# STM32WL54xx register map
File version: 1.0
Registers are 32-bit, read-write, reset 0x0 unless marked. A register's access mark holds for its fields unless they carry their own. Offsets are from the block's base; [hi:lo] are bit positions; {n}, {i} and the like mark numbered series.

## AES — AES hardware accelerator
Base 0x58001800
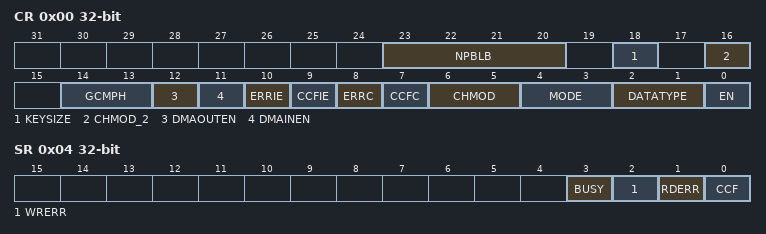
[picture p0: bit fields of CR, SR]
0x00 CR — AES control register
  [23:20] NPBLB — Number of padding bytes in last payload block
  [18] KEYSIZE — Key size selection
  [16] CHMOD_2 — AES Chaining Mode
  [14:13] GCMPH — GCM Phase
  [12] DMAOUTEN — Enable data output phase DMA management
  [11] DMAINEN — Enable data input phase DMA management
  [10] ERRIE — Error Interrupt Enable
  [9] CCFIE — Computation Complete Flag Interrupt Enable
  [8] ERRC — Error Clear
  [7] CCFC — Computation Complete Flag Clear
  [6:5] CHMOD — AES Chaining Mode
  [4:3] MODE — AES Mode Of Operation
  [2:1] DATATYPE — Data type selection
  [0] EN — AES Enable
0x04 SR — AES status register
  [3] BUSY — Busy Flag
  [2] WRERR — Write Error Flag
  [1] RDERR — Read Error Flag
  [0] CCF — Computation Complete Flag
0x08 DINR — AES data input register
  [31:0] DINR — AES Data Input Register
0x0C DOUTR — AES data output register
  [31:0] DOUTR — AES Data Output Register
{0x10+4i} KEYR{i} (i=0..3) — AES key register {i}
  [31:0] KEYR{i} — AES Key Register {i}
{0x20+4i} IVR{i} (i=0..3) — AES initialization vector register {i}
  [31:0] IVR{i} — AES Initialization Vector Register {i}
{0x20+4i} KEYR{i} (i=4..7) — AES key register {i}
  [31:0] KEYR{i} — AES Key Register {i}
{0x40+4i} SUSP{i}R (i=0..7) — AES Suspend register {i}
  [31:0] SUSP{i}R — AES Suspend registers {i}

## PKA — Public Key Accelerator (PKA)
Base 0x58002000
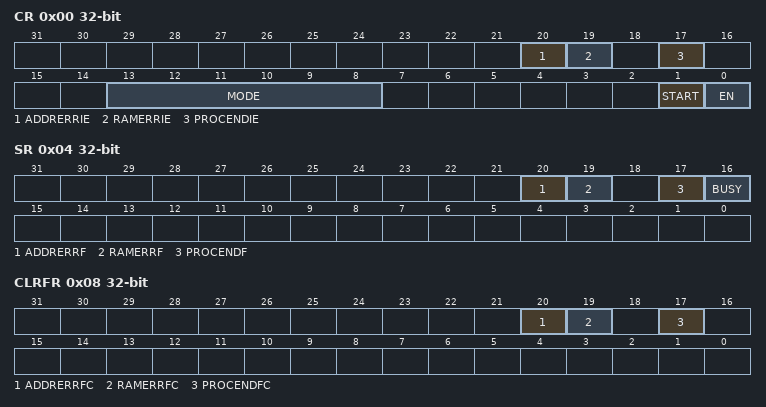
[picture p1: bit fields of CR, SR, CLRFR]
0x00 CR — PKA control register
  [20] ADDRERRIE — RAM error interrupt enable
  [19] RAMERRIE — RAM error interrupt enable
  [17] PROCENDIE — End of operation interrupt enable
  [13:8] MODE — MODE[5:0] PKA operation code
  [1] START — Start operation
  [0] EN — PKA enable
0x04 SR — PKA status register
  [20] ADDRERRF — Address error flag
  [19] RAMERRF — PKA RAM error flag
  [17] PROCENDF — PKA end of operation flag
  [16] BUSY — PKA operation is in progress
0x08 CLRFR — PKA clear flag register
  [20] ADDRERRFC — Clear address error flag
  [19] RAMERRFC — Clear PKA RAM error flag
  [17] PROCENDFC — Clear PKA end of operation flag
{0x400+4i} RAM[{i}] (i=0..893)

## GTZC_TZSC — Global Security Controller
Base 0x58004400
0x00 CR — TZSC control register
  [0] LCK
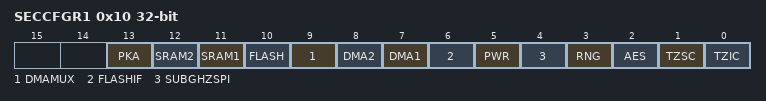
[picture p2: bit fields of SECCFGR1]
0x10 SECCFGR1 — TZSC secure configuration register 1
  [13] PKA, [12] SRAM2, [11] SRAM1, [10] FLASH, [9] DMAMUX, [8] DMA2, [7] DMA1, [6] FLASHIF, [5] PWR, [4] SUBGHZSPI, [3] RNG, [2] AES, [1] TZSC, [0] TZIC
0x20 PRIVCFGR1 — TZSC privilege configuration register 1
0x130 MPCWM1_UPWMR — TZSC Unprivileged Water Mark 1 register
0x134 MPCWM1_UPWWMR — TZSC Unprivileged Writable Water Mark 1 register
0x138 MPCWM2_UPWMR — TZSC Unprivileged Water Mark 2 register
0x140 MPCWM3_UPWMR — TZSC Unprivileged Water Mark 2 register

## GTZC_TZIC
Base 0x58004800
0x00 IER1 — TZIC interrupt enable register 1
0x10 MISR1 — TZIC interrupt status register 1
0x20 ICR1 — TZIC interrupt clear register 1

## DBGMCU — Debug MCU
Base 0xE0042000
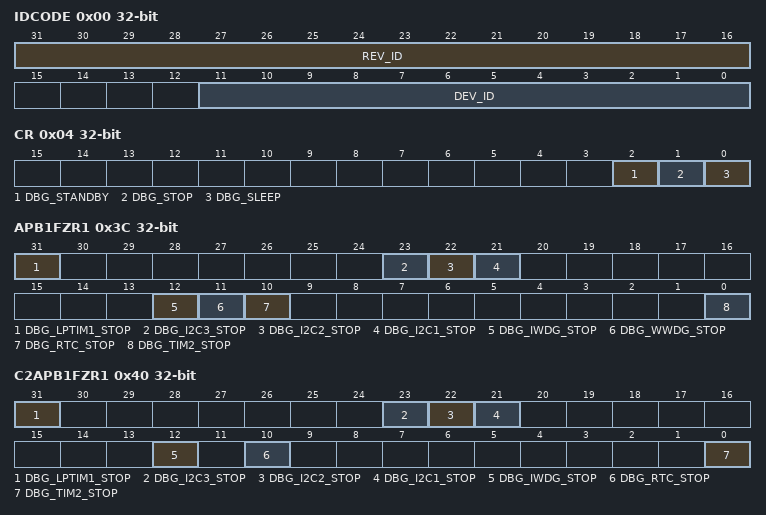
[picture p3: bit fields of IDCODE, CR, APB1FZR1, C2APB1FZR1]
0x00 IDCODE — MCU device ID code
  [31:16] REV_ID, [11:0] DEV_ID
0x04 CR — Debug MCU configuration register
  [2] DBG_STANDBY, [1] DBG_STOP, [0] DBG_SLEEP
0x3C APB1FZR1 — Debug MCU CPU1 APB1 freeze register
  [31] DBG_LPTIM1_STOP, [23] DBG_I2C3_STOP, [22] DBG_I2C2_STOP, [21] DBG_I2C1_STOP, [12] DBG_IWDG_STOP, [11] DBG_WWDG_STOP, [10] DBG_RTC_STOP, [0] DBG_TIM2_STOP
0x40 C2APB1FZR1 — Debug MCU CPU2 APB1 freeze register
  [31] DBG_LPTIM1_STOP, [23] DBG_I2C3_STOP, [22] DBG_I2C2_STOP, [21] DBG_I2C1_STOP, [12] DBG_IWDG_STOP, [10] DBG_RTC_STOP, [0] DBG_TIM2_STOP
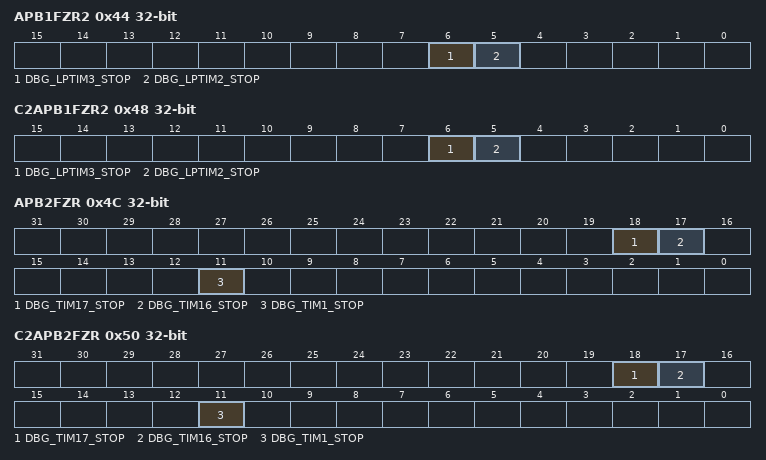
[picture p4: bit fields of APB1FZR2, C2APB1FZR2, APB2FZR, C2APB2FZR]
0x44 APB1FZR2 — Debug MCU CPU1 APB1 freeze register
  [6] DBG_LPTIM3_STOP, [5] DBG_LPTIM2_STOP
0x48 C2APB1FZR2 — Debug MCU CPU2 APB1 freeze register
  [6] DBG_LPTIM3_STOP, [5] DBG_LPTIM2_STOP
0x4C APB2FZR — Debug MCU CPU1 APB2 freeze register
  [18] DBG_TIM17_STOP, [17] DBG_TIM16_STOP, [11] DBG_TIM1_STOP
0x50 C2APB2FZR — Debug MCU CPU2 APB2 freeze register
  [18] DBG_TIM17_STOP, [17] DBG_TIM16_STOP, [11] DBG_TIM1_STOP
